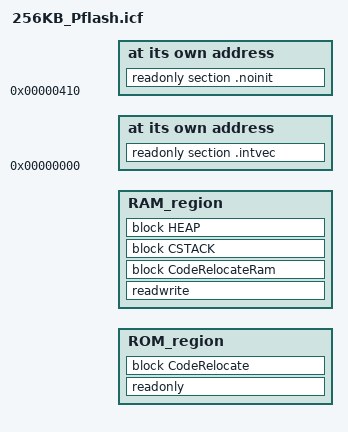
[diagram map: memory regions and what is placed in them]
/*###ICF### Section handled by ICF editor, don't touch! ****/
/*-Editor annotation file-*/
/* IcfEditorFile="$TOOLKIT_DIR$\config\ide\IcfEditor\cortex_v1_0.xml" */
/* Memories size definition                                           */
define symbol __ICFEDIT_size_pflash__ = (256*1024);
define symbol __ICFEDIT_size_ram__    = (32*1024);
define symbol __ICFEDIT_size_cstack__ = (1*1024);
define symbol __ICFEDIT_size_heap__   = (2*1024);
define symbol __RAM_Vector_used       = 0;// 0 not used, 1 used;

/*-Memory Regions-*/
define symbol __ICFEDIT_region_ROM_start__ = 0x0;
define symbol __ICFEDIT_region_ROM_end__   = __ICFEDIT_size_pflash__;
define symbol __ICFEDIT_region_SRAML_end__ = 0x20000000;
if (__RAM_Vector_used)
  {
  define symbol __ICFEDIT_region_RAM_start__ = __ICFEDIT_region_SRAML_end__ - __ICFEDIT_size_ram__/4 + 0x410;
  }
else
  {
  define symbol __ICFEDIT_region_RAM_start__ = __ICFEDIT_region_SRAML_end__ - __ICFEDIT_size_ram__/4;
  }  
define symbol __region_SRAMU_start__     = __ICFEDIT_region_SRAML_end__;
define symbol __ICFEDIT_region_RAM_end__ = __region_SRAMU_start__ + (__ICFEDIT_size_ram__*3)/4;

/*-Specials-*/
define symbol __ICFEDIT_intvec_start__ = __ICFEDIT_region_ROM_start__;
define symbol __code_start__           = 0x00000410;

/**** End of ICF editor section. ###ICF###*/

define exported symbol __VECTOR_TABLE      = 0x00000000;
if (__RAM_Vector_used)
  {
    define exported symbol __VECTOR_RAM = __ICFEDIT_region_RAM_start__ - 0x410;
  }
else
  {
    define exported symbol __VECTOR_RAM = __VECTOR_TABLE;
  }

define exported symbol __BOOT_STACK_ADDRESS = __ICFEDIT_region_RAM_end__ - 8;


define memory mem with size = 4G;
define region ROM_region   = mem:[from __ICFEDIT_region_ROM_start__   to __ICFEDIT_region_ROM_end__];
define region RAM_region   = mem:[from __ICFEDIT_region_RAM_start__   to __ICFEDIT_region_RAM_end__];

define block CSTACK    with alignment = 8, size = __ICFEDIT_size_cstack__   { };
define block HEAP      with alignment = 8, size = __ICFEDIT_size_heap__     { };

initialize manually { readwrite };
initialize manually { section .data};
initialize manually { section .textrw };
do not initialize  { section .noinit };

define block CodeRelocate { section .textrw_init };
define block CodeRelocateRam { section .textrw };

place at address mem:__ICFEDIT_intvec_start__ { readonly section .intvec };
place at address mem:__code_start__ { readonly section .noinit };

place in ROM_region   { readonly, block CodeRelocate};

place in RAM_region   { readwrite, block CodeRelocateRam,
                        block CSTACK, block HEAP };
